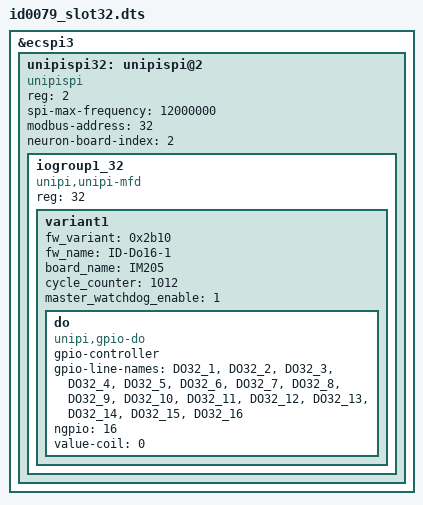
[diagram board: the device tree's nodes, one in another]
/dts-v1/;


/plugin/;

/ {
	fragment@1 {
		
		target = <&ecspi3>;
		__overlay__ {
			status = "okay";
			#address-cells = <1>;
			#size-cells = <0>;

			unipispi32: unipispi@2 {
				compatible = "unipispi";
				reg = <2>;
				status = "okay";
				spi-max-frequency = <12000000>;
				modbus-address = <32>;
				neuron-board-index = <2>;
			};
		};

	};

	fragment@2 {
		target = <&unipispi32>;
		__overlay__ {
			#address-cells = <1>;
			#size-cells = <0>;

			iogroup1_32 {
				reg = <32>;
				compatible = "unipi,unipi-mfd", "iogroup";
				variant1 { 
					fw_variant = <0x2b10>;
					fw_name = "ID-Do16-1";
					board_name = "IM205";
					cycle_counter = <1012>;
					master_watchdog_enable = <1>;

					do {
						compatible = "unipi,gpio-do";
						gpio-controller;
						#gpio-cells = <2>;
						gpio-line-names = "DO32_1", "DO32_2" , "DO32_3", "DO32_4", "DO32_5", "DO32_6", "DO32_7", "DO32_8", "DO32_9", "DO32_10", "DO32_11", "DO32_12", "DO32_13", "DO32_14", "DO32_15", "DO32_16";
						ngpio = <16>;
						value-coil = <0>;
					};
				};
			};
		};
	};
};
